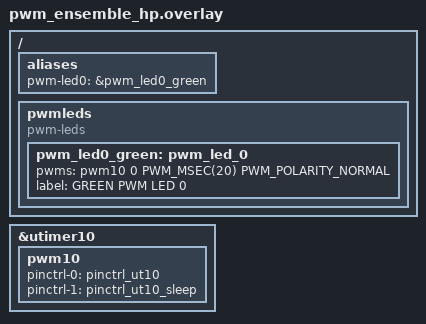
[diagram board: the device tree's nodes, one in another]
/* Copyright (C) 2026 Alif Semiconductor - All Rights Reserved.
 * Use, distribution and modification of this code is permitted under the
 * terms stated in the Alif Semiconductor Software License Agreement
 *
 * You should have received a copy of the Alif Semiconductor Software
 * License Agreement with this file. If not, please write to:
 * contact@alifsemi.com, or visit: https://alifsemi.com/license
 *
 */
#include "pm_mram_hp.overlay"

/ {
	aliases {
		pwm-led0 = &pwm_led0_green;
	};

	pwmleds {
		compatible = "pwm-leds";
		pwm_led0_green: pwm_led_0 {
			pwms = <&pwm10 0 PWM_MSEC(20) PWM_POLARITY_NORMAL>;
			label = "GREEN PWM LED 0";
		};
	};

};

&utimer10 {
	status = "okay";

	pwm10: pwm10 {
		pinctrl-0 = <&pinctrl_ut10>;
		pinctrl-1 = <&pinctrl_ut10_sleep>;
		pinctrl-names = "default", "sleep";
		status = "okay";
	};
};
